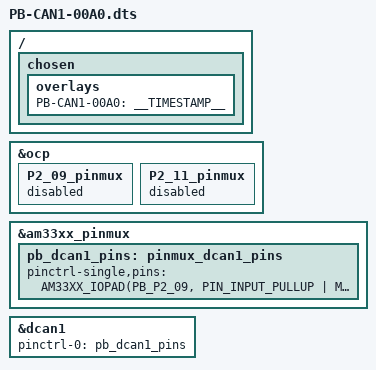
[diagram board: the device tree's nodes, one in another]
/*
 * Copyright (C) 2015 Robert Nelson <robertcnelson@gmail.com>
 *
 * Virtual cape for CAN1 on connector pins PocketBeagle P2.09 and P2.11
 *
 * This program is free software; you can redistribute it and/or modify
 * it under the terms of the GNU General Public License version 2 as
 * published by the Free Software Foundation.
 */
/dts-v1/;
/plugin/;

#include <dt-bindings/pinctrl/am33xx.h>
#include <dt-bindings/board/am335x-pb-base.h>

/ {
	/*
	 * Helper to show loaded overlays under: /proc/device-tree/chosen/overlays/
	 */
	fragment@0 {
		target-path="/";
		__overlay__ {

			chosen {
				overlays {
					PB-CAN1-00A0 = __TIMESTAMP__;
				};
			};
		};
	};

	/*
	 * Free up the pins used by the cape from the pinmux helpers.
	 */
	fragment@1 {
		target = <&ocp>;
		__overlay__ {
			P2_09_pinmux { status = "disabled"; };	/* P2_09: uart1_txd.d_can1_rx */
			P2_11_pinmux { status = "disabled"; };	/* P2_11: uart1_rxd.d_can1_tx */
		};
	};

	fragment@2 {
		target = <&am33xx_pinmux>;
		__overlay__ {
			pb_dcan1_pins: pinmux_dcan1_pins {
				/* https://github.com/beagleboard/BeagleBoard-DeviceTrees/blob/v4.19.x-ti/src/arm/am335x-pocketbeagle.dts#L320 */
				pinctrl-single,pins = <
					AM33XX_IOPAD(PB_P2_09, PIN_INPUT_PULLUP | MUX_MODE2)	/* uart1_txd.dcan1_rx */
					AM33XX_IOPAD(PB_P2_11, PIN_OUTPUT_PULLUP | MUX_MODE2)	/* uart1_rxd.dcan1_tx */
				>;
			};
		};
	};

	fragment@3 {
		target = <&dcan1>;
		__overlay__ {
			status = "okay";
			pinctrl-names = "default";
			pinctrl-0 = <&pb_dcan1_pins>;
		};
	};
};
